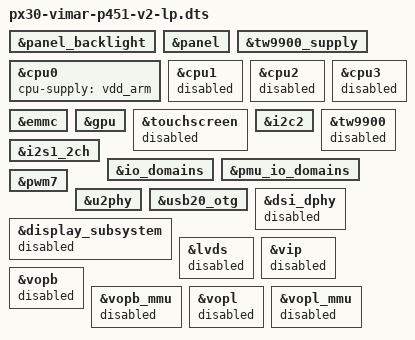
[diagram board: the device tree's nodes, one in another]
// SPDX-License-Identifier: (GPL-2.0+ OR MIT)
/*
 * Copyright (c) 2018 Fuzhou Rockchip Electronics Co., Ltd
 * (C) Copyright 2019 Vimar
 */

/dts-v1/;
#include "px30-vimar-p451-v2.dts"

&panel_backlight {
	status = "okay";
};

&panel {
	status = "okay";

};

&tw9900_supply {
	status = "okay";
};

&cpu0 {
	cpu-supply = <&vdd_arm>;
};

&cpu1 {
	status = "disabled";
};

&cpu2 {
	status = "disabled";
};

&cpu3 {
	status = "disabled";
};

&emmc {
	status = "okay";
};

&gpu {
	status = "okay";
};

&touchscreen {
	status = "disabled";
};

&i2c2 {
	status = "okay";
};

&tw9900 {
	status = "disabled";
};

&i2s1_2ch {
	status = "okay";
};

&io_domains {
	status = "okay";
};

&pmu_io_domains {
	status = "okay";
};

&pwm7 {
	status = "okay";
};

&u2phy {
	status = "okay";
};

&usb20_otg {
	status = "okay";
};

&display_subsystem {
	status = "disabled";
};

&dsi_dphy {
	status = "disabled";
};

&lvds {
	status = "disabled";
};

&vip {
	status = "disabled";
};

&vopb {
	status = "disabled";
};

&vopb_mmu {
	status = "disabled";
};

&vopl {
	status = "disabled";
};

&vopl_mmu {
	status = "disabled";
};
